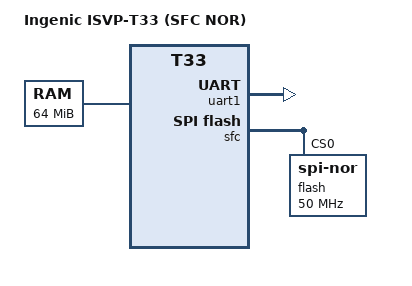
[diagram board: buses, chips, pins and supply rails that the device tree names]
// SPDX-License-Identifier: GPL-2.0+

/dts-v1/;

#include <dt-bindings/gpio/gpio.h>
#include "t33.dtsi"

/ {
	compatible = "ingenic,isvp-t33", "ingenic,t33";
	model = "Ingenic ISVP-T33 (SFC NOR)";

	aliases {
		serial1 = &uart1;
	};

	chosen {
		stdout-path = "serial1:115200n8";
	};

	memory {
		device_type = "memory";
		reg = <0x0 0x04000000>;	/* 64 MB DDR2 (M14D5121632A) */
	};
};

&uart1 {
	status = "okay";
};

&sfc {
	status = "okay";

	flash@0 {
		compatible = "jedec,spi-nor";
		reg = <0>;
		spi-max-frequency = <50000000>;
	};
};
